# PIC32MZ2048EFM144 register map
Vendor: Microchip
Registers are 32-bit, read-write, reset 0x0 unless marked. A register's access mark holds for its fields unless they carry their own. Addresses are absolute, and some are shared; only a register's first bit layout is shown; [hi:lo] are bit positions.

## I2C1
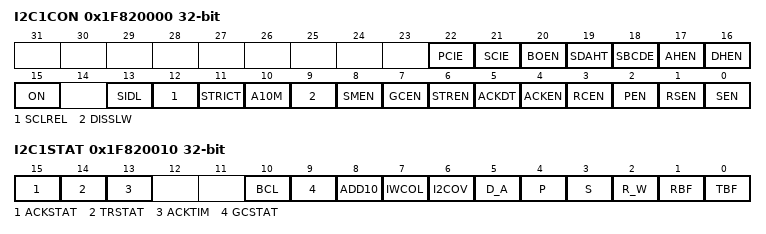
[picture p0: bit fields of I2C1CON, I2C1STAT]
0x1F820000 I2C1CON reset not defined — (power-on value ---------00000000x01000000000000)
  [22] PCIE, [21] SCIE, [20] BOEN, [19] SDAHT, [18] SBCDE, [17] AHEN, [16] DHEN, [15] ON, [13] SIDL, [12] SCLREL, [11] STRICT, [10] A10M, [9] DISSLW, [8] SMEN, [7] GCEN, [6] STREN, [5] ACKDT, [4] ACKEN, [3] RCEN, [2] PEN, [1] RSEN, [0] SEN
0x1F820010 I2C1STAT
  [15] ACKSTAT ro
  [14] TRSTAT ro
  [13] ACKTIM ro
  [10] BCL — (can only be cleared)
  [9] GCSTAT ro
  [8] ADD10 ro
  [7] IWCOL — (can only be cleared)
  [6] I2COV — (can only be cleared)
  [5] D_A ro
  [4] P — (can only be cleared)
  [3] S — (can only be cleared)
  [2] R_W ro
  [1] RBF ro
  [0] TBF ro
0x1F820020 I2C1ADD
  [9:0] I2CADD
0x1F820030 I2C1MSK
  [9:0] I2CMSK
0x1F820040 I2C1BRG
  [15:0] I2CBRG
0x1F820050 I2C1TRN wo reset 0xFF
  [7:0] I2CTRN
0x1F820060 I2C1RCV ro
  [7:0] I2CRCV

## I2C2
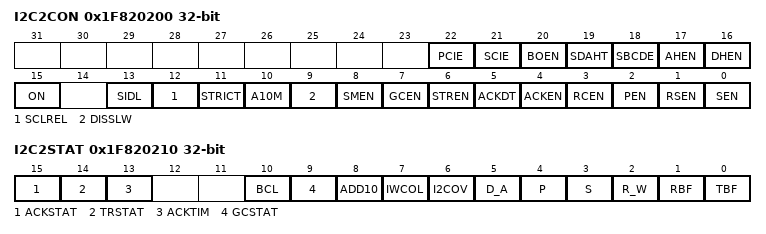
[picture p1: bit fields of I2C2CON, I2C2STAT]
0x1F820200 I2C2CON reset not defined — (power-on value ---------00000000x01000000000000)
  [22] PCIE, [21] SCIE, [20] BOEN, [19] SDAHT, [18] SBCDE, [17] AHEN, [16] DHEN, [15] ON, [13] SIDL, [12] SCLREL, [11] STRICT, [10] A10M, [9] DISSLW, [8] SMEN, [7] GCEN, [6] STREN, [5] ACKDT, [4] ACKEN, [3] RCEN, [2] PEN, [1] RSEN, [0] SEN
0x1F820210 I2C2STAT
  [15] ACKSTAT ro
  [14] TRSTAT ro
  [13] ACKTIM ro
  [10] BCL — (can only be cleared)
  [9] GCSTAT ro
  [8] ADD10 ro
  [7] IWCOL — (can only be cleared)
  [6] I2COV — (can only be cleared)
  [5] D_A ro
  [4] P — (can only be cleared)
  [3] S — (can only be cleared)
  [2] R_W ro
  [1] RBF ro
  [0] TBF ro
0x1F820220 I2C2ADD
  [9:0] I2CADD
0x1F820230 I2C2MSK
  [9:0] I2CMSK
0x1F820240 I2C2BRG
  [15:0] I2CBRG
0x1F820250 I2C2TRN wo reset 0xFF
  [7:0] I2CTRN
0x1F820260 I2C2RCV ro
  [7:0] I2CRCV

## I2C3
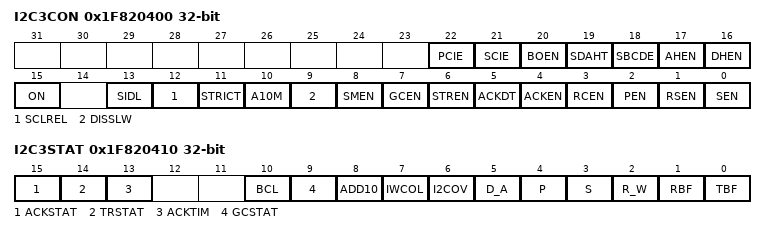
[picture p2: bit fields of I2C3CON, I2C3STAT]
0x1F820400 I2C3CON reset not defined — (power-on value ---------00000000x01000000000000)
  [22] PCIE, [21] SCIE, [20] BOEN, [19] SDAHT, [18] SBCDE, [17] AHEN, [16] DHEN, [15] ON, [13] SIDL, [12] SCLREL, [11] STRICT, [10] A10M, [9] DISSLW, [8] SMEN, [7] GCEN, [6] STREN, [5] ACKDT, [4] ACKEN, [3] RCEN, [2] PEN, [1] RSEN, [0] SEN
0x1F820410 I2C3STAT
  [15] ACKSTAT ro
  [14] TRSTAT ro
  [13] ACKTIM ro
  [10] BCL — (can only be cleared)
  [9] GCSTAT ro
  [8] ADD10 ro
  [7] IWCOL — (can only be cleared)
  [6] I2COV — (can only be cleared)
  [5] D_A ro
  [4] P — (can only be cleared)
  [3] S — (can only be cleared)
  [2] R_W ro
  [1] RBF ro
  [0] TBF ro
0x1F820420 I2C3ADD
  [9:0] I2CADD
0x1F820430 I2C3MSK
  [9:0] I2CMSK
0x1F820440 I2C3BRG
  [15:0] I2CBRG
0x1F820450 I2C3TRN wo reset 0xFF
  [7:0] I2CTRN
0x1F820460 I2C3RCV ro
  [7:0] I2CRCV

## I2C4
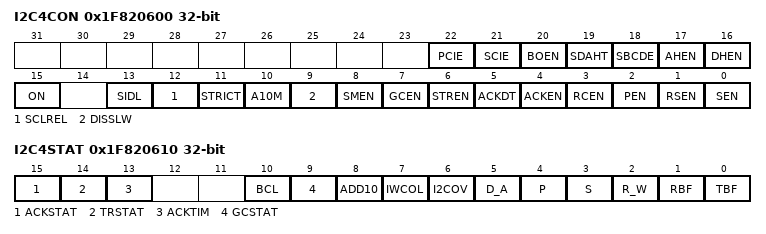
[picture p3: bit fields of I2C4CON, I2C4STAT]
0x1F820600 I2C4CON reset not defined — (power-on value ---------00000000x01000000000000)
  [22] PCIE, [21] SCIE, [20] BOEN, [19] SDAHT, [18] SBCDE, [17] AHEN, [16] DHEN, [15] ON, [13] SIDL, [12] SCLREL, [11] STRICT, [10] A10M, [9] DISSLW, [8] SMEN, [7] GCEN, [6] STREN, [5] ACKDT, [4] ACKEN, [3] RCEN, [2] PEN, [1] RSEN, [0] SEN
0x1F820610 I2C4STAT
  [15] ACKSTAT ro
  [14] TRSTAT ro
  [13] ACKTIM ro
  [10] BCL — (can only be cleared)
  [9] GCSTAT ro
  [8] ADD10 ro
  [7] IWCOL — (can only be cleared)
  [6] I2COV — (can only be cleared)
  [5] D_A ro
  [4] P — (can only be cleared)
  [3] S — (can only be cleared)
  [2] R_W ro
  [1] RBF ro
  [0] TBF ro
0x1F820620 I2C4ADD
  [9:0] I2CADD
0x1F820630 I2C4MSK
  [9:0] I2CMSK
0x1F820640 I2C4BRG
  [15:0] I2CBRG
0x1F820650 I2C4TRN wo reset 0xFF
  [7:0] I2CTRN
0x1F820660 I2C4RCV ro
  [7:0] I2CRCV

## I2C5
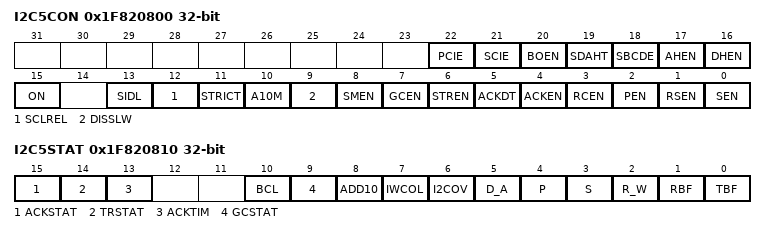
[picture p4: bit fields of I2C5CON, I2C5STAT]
0x1F820800 I2C5CON reset not defined — (power-on value ---------00000000x01000000000000)
  [22] PCIE, [21] SCIE, [20] BOEN, [19] SDAHT, [18] SBCDE, [17] AHEN, [16] DHEN, [15] ON, [13] SIDL, [12] SCLREL, [11] STRICT, [10] A10M, [9] DISSLW, [8] SMEN, [7] GCEN, [6] STREN, [5] ACKDT, [4] ACKEN, [3] RCEN, [2] PEN, [1] RSEN, [0] SEN
0x1F820810 I2C5STAT
  [15] ACKSTAT ro
  [14] TRSTAT ro
  [13] ACKTIM ro
  [10] BCL — (can only be cleared)
  [9] GCSTAT ro
  [8] ADD10 ro
  [7] IWCOL — (can only be cleared)
  [6] I2COV — (can only be cleared)
  [5] D_A ro
  [4] P — (can only be cleared)
  [3] S — (can only be cleared)
  [2] R_W ro
  [1] RBF ro
  [0] TBF ro
0x1F820820 I2C5ADD
  [9:0] I2CADD
0x1F820830 I2C5MSK
  [9:0] I2CMSK
0x1F820840 I2C5BRG
  [15:0] I2CBRG
0x1F820850 I2C5TRN wo reset 0xFF
  [7:0] I2CTRN
0x1F820860 I2C5RCV ro
  [7:0] I2CRCV
